# GD32H77x_78x register map
File version: 1.0
CPU: CM7 r1p2, little endian, MPU, FPU, 4 interrupt priority bits
Registers are 32-bit, read-write, reset 0x0 unless marked. A register's access mark holds for its fields unless they carry their own. Offsets are from the block's base; [hi:lo] are bit positions; {n}, {i} and the like mark numbered series.

## SAFE_CHANNEL_1 — HDSL Safe Channel 1 Interface
Base 0x4000DA00
0x09 EDGES 8-bit ro — HDSL safe channel 1 edge register
  [7:0] EDGES — Identification of edges in the cable signal
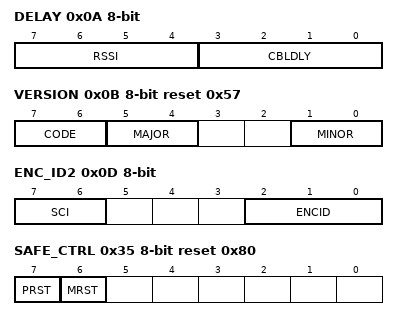
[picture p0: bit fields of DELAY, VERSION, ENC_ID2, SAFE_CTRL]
0x0A DELAY 8-bit ro — HDSL safe channel 1 run time delay register
  [7:4] RSSI — Indication of the received signal strength
  [3:0] CBLDLY — 4-bit value for cable delay
0x0B VERSION 8-bit ro reset 0x57 — HDSL safe channel 1 version register
  [7:6] CODE — Type of module
  [5:4] MAJOR — Major release number
  [1:0] MINOR — Minor release number
0x0D ENC_ID2 8-bit ro — HDSL safe channel 1 encoder ID 2 register
  [7:6] SCI — Indication of special characters
  [2:0] ENCID — Encoder designation code bit 19 to bit 16
0x0E ENC_ID1 8-bit ro — HDSL safe channel 1 encoder ID 1 register
  [7:0] ENCID — Encoder designation code bit 15 to bit 8
0x0F ENC_ID0 8-bit ro — HDSL safe channel 1 encoder ID 0 register
  [7:0] ENCID — Encoder designation code bit 7 to bit 0
0x19 VPOS4 8-bit ro — HDSL safe position channel 1 byte 4 register
  [7:0] VPOS — Safe position, byte 4
0x1A VPOS3 8-bit ro — HDSL safe position channel 1 byte 3 register
  [7:0] VPOS — Safe position, byte 3
0x1B VPOS2 8-bit ro — HDSL safe position channel 1 byte 2 register
  [7:0] VPOS — Safe position, byte 2
0x1C VPOS1 8-bit ro — HDSL safe position channel 1 byte 1 register
  [7:0] VPOS — Safe position, byte 1
0x1D VPOS0 8-bit ro — HDSL safe position channel 1 byte 0 register
  [7:0] VPOS — Safe position, byte 0
0x1E VPOSCRC_H 8-bit ro — HDSL high byte position checksum channel 1 register
  [7:0] VPOSCRCH — CRC of the safe position, byte 1
0x1F VPOSCRC_L 8-bit ro — HDSL low byte position checksum channel 1 register
  [7:0] VPOSCRCL — CRC of the safe position, byte 0
0x35 SAFE_CTRL 8-bit reset 0x80 — HDSL safe system control register
  [7] PRST — Protocol reset
  [6] MRST — Message reset
0x36 SAFE_SUM 8-bit ro — HDSL safe status summary register
  [7:0] SSUM — Status summary bit
0x37 S_PC_DATA 8-bit ro — HDSL parameters channel short message register
  [7:0] SPCDATA — Short message parameter channel data
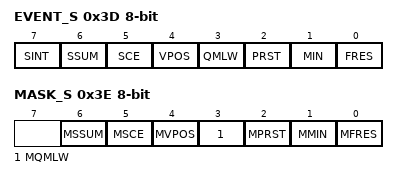
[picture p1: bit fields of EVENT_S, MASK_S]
0x3D EVENT_S 8-bit ro — HDSL safe event register
  [7] SINT — Safe interrupt status
  [6] SSUM — Remote event monitoring
  [5] SCE — Error on the Safe Channel
  [4] VPOS — Safe position error
  [3] QMLW — Quality monitoring low-value warning
  [2] PRST — Protocol reset warning
  [1] MIN — Message init
  [0] FRES — Channel free for 'short message'
0x3E MASK_S 8-bit wo — HDSL safe event mask register
  [6] MSSUM — Mask for remote event monitoring
  [5] MSCE — Mask for transmission errors on the Safe Channel
  [4] MVPOS — Mask for safe position error
  [3] MQMLW — Mask for low-quality monitoring value warning
  [2] MPRST — Mask for protocol reset warning
  [1] MMIN — Mask for message initialization confirmation
  [0] MFRES — Mask for channel free for 'short message'
{0x40+i} ENC_ST{i} 8-bit ro (i=0..7) — HDSL encoder status {i} register
  [7:0] ENCST — Encoder status, byte {i}
0x7C SRSSI 8-bit ro — HDSL slave RSSI register
  [2:0] SRSSI — Value of the Slave RSSI
0x7E MAIL 8-bit wo — HDSL slave mail register
  [7:0] MAIL — Slave-Mail
0x7F PING 8-bit — HDSL ping register
  [7:0] PING — Slave-Ping.

## SAFE_CHANNEL_2 — HDSL Safe Channel 2 Interface Registers
Base 0x4000DB00
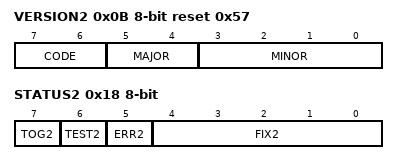
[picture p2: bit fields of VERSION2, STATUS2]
0x0B VERSION2 8-bit ro reset 0x57 — HDSL version in safe channel 2 register
  [7:6] CODE — Type of module01: HDSL MasterOthers: Reserved
  [5:4] MAJOR — Major release numberThe current version is 1.
  [3:0] MINOR — Minor release numberThe current version is 7.
0x0F ENC2_ID 8-bit ro — HDSL encoder ID in safe channel 2 register
  [7:0] ENC2ID — Designation of the safe channel 2 channel
0x18 STATUS2 8-bit ro — HDSL safe channel 2 status register
  [7] TOG2 — Safe Channel 2 Toggle
  [6] TEST2 — Safe Channel 2 Test
  [5] ERR2 — Safe Channel 2 Position Error
  [4:0] FIX2 — Safe Channel 2 Fixed Bit Pattern
0x19 VPOS2_4 8-bit ro — HDSL safe position channel 2 byte 4 register
  [7:0] VPOS2 — Safe position, Channel 2, byte 4
0x1A VPOS2_3 8-bit ro — HDSL safe position channel 2 byte 3 register
  [7:0] VPOS2 — Safe position, Channel 2, byte 3
0x1B VPOS2_2 8-bit ro — HDSL safe position channel 2 byte 2 register
  [7:0] VPOS2 — Safe position, Channel 2, byte 2
0x1C VPOS2_1 8-bit ro — HDSL safe position channel 2 byte 1 register
  [7:0] VPOS2 — Safe position, Channel 2, byte 1
0x1D VPOS2_0 8-bit ro — HDSL safe position channel 2 byte 0 register
  [7:0] VPOS2 — Safe position, Channel 2, byte 0
0x1E VPOSCRC2_H 8-bit ro — HDSL high byte position checksum channel 2 register
  [7:0] VPOSCRC2H — CRC of the safe position 2, bit 15 to bit 8
0x1F VPOSCRC2_L 8-bit ro — HDSL low byte position checksum channel 2 register
  [7:0] VPOSCRC2L — CRC of the safe position 2, bit 7 to bit 0
